# GD32VW553x register map
File version: 1.0
CPU: other RISC-V, little endian, no MPU, FPU
Registers are 32-bit, read-write, reset 0x0 unless marked. A register's access mark holds for its fields unless they carry their own. Offsets are from the block's base; [hi:lo] are bit positions; {n}, {i} and the like mark numbered series.

## RCU — Reset and clock unit
Base 0x40023800
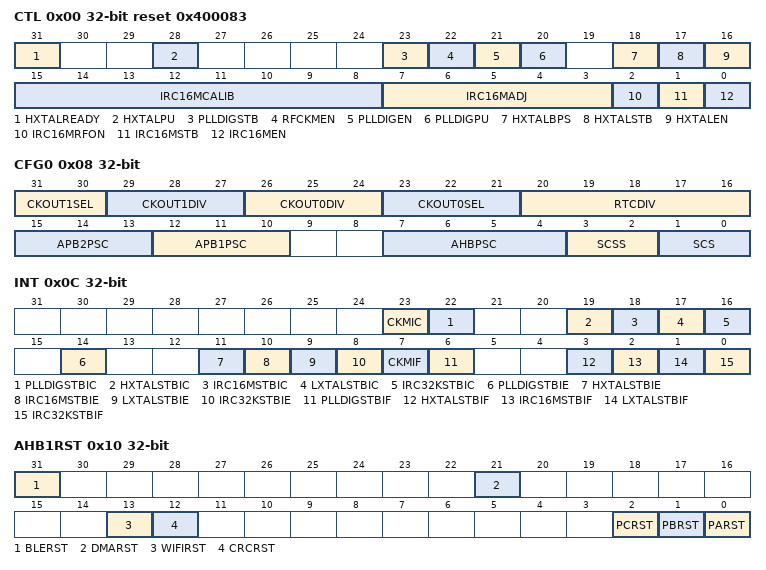
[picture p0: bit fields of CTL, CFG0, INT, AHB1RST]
0x00 CTL access per field reset 0x400083 — Control register
  [31] HXTALREADY rw — High speed crystal oscillator ready, set by software, which can be written when HXTALEN is off
  [28] HXTALPU rw — High speed crystal oscillator (HXTAL) power up, which can be written when HXTALEN is off
  [23] PLLDIGSTB ro — PLLDIG clock stabilization flag
  [22] RFCKMEN rw — HXTAL clock monitor enable, check RF XTAL
  [21] PLLDIGEN rw — PLLDIG enable, this bit cannot be reset if the PLLDIG clock is used as the system clock
  [20] PLLDIGPU rw — PLLDIG power up, this bit cannot be reset if the PLLDIG clock is used as the system clock
  [18] HXTALBPS rw — High speed crystal oscillator (HXTAL) clock bypass mode enable
  [17] HXTALSTB ro — High speed crystal oscillator (HXTAL) clock stabilization flag
  [16] HXTALEN rw — High speed crystal oscillator (HXTAL) enable
  [15:8] IRC16MCALIB ro — Internal 16 MHz RC Oscillator calibration value register
  [7:3] IRC16MADJ rw — Internal 16 MHz RC oscillator clock trim adjust value
  [2] IRC16MRFON rw — Internal 16 MHz RC RF differential clock signal enable
  [1] IRC16MSTB ro — IRC16M internal 16MHz RC oscillator stabilization flag
  [0] IRC16MEN rw — Internal 16 MHz RC oscillator enable
0x04 PLL — PLL(Phase Lock Loop) register
  [15] PLLDIGSEL — PLLDIG clock source selection
0x08 CFG0 access per field — Clock configuration register 0
  [31:30] CKOUT1SEL rw — CKOUT1 clock source selection
  [29:27] CKOUT1DIV rw — The CK_OUT1 divider which the CK_OUT1 frequency can be reduced
  [26:24] CKOUT0DIV rw — The CK_OUT0 divider which the CK_OUT0 frequency can be reduced
  [23:21] CKOUT0SEL rw — CKOUT0 clock source selection
  [20:16] RTCDIV rw — RTC clock divider factor
  [15:13] APB2PSC rw — APB2 prescaler selection
  [12:10] APB1PSC rw — APB1 prescaler selection
  [7:4] AHBPSC rw — AHB prescaler selection
  [3:2] SCSS ro — System clock switch status
  [1:0] SCS rw — System clock switch
0x0C INT access per field — Clock interrupt register
  [23] CKMIC wo — HXTAL clock stuck interrupt clear
  [22] PLLDIGSTBIC wo — PLLDIG stabilization interrupt clear
  [19] HXTALSTBIC wo — HXTAL stabilization interrupt clear
  [18] IRC16MSTBIC wo — IRC16M stabilization interrupt clear
  [17] LXTALSTBIC wo — LXTAL stabilization interrupt clear
  [16] IRC32KSTBIC wo — IRC32K Stabilization interrupt clear
  [14] PLLDIGSTBIE rw — PLLDIG stabilization interrupt enable
  [11] HXTALSTBIE rw — HXTAL stabilization interrupt enable
  [10] IRC16MSTBIE rw — IRC16M stabilization interrupt enable
  [9] LXTALSTBIE rw — LXTAL stabilization interrupt enable
  [8] IRC32KSTBIE rw — IRC32K stabilization interrupt enable
  [7] CKMIF ro — HXTAL clock stuck interrupt flag
  [6] PLLDIGSTBIF ro — PLLDIG stabilization interrupt flag
  [3] HXTALSTBIF ro — HXTAL stabilization interrupt flag
  [2] IRC16MSTBIF ro — IRC16M stabilization interrupt flag
  [1] LXTALSTBIF ro — LXTAL stabilization interrupt flag
  [0] IRC32KSTBIF ro — IRC32K stabilization interrupt flag
0x10 AHB1RST — AHB1 reset register
  [31] BLERST — BLE reset
  [21] DMARST — DMA reset
  [13] WIFIRST — WIFI reset
  [12] CRCRST — CRC reset
  [2] PCRST — GPIO port C reset
  [1] PBRST — GPIO port B reset
  [0] PARST — GPIO port A reset
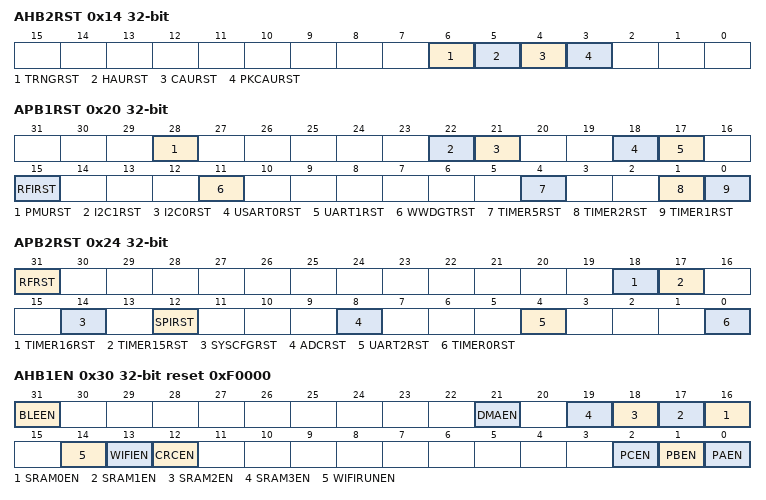
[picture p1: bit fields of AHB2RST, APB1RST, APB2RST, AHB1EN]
0x14 AHB2RST — AHB2 reset register
  [6] TRNGRST — TRNG reset
  [5] HAURST — HAU reset
  [4] CAURST — CAU reset
  [3] PKCAURST — PKCAU reset
0x18 AHB3RST — AHB3 reset register
  [1] QSPIRST — QSPI reset
0x20 APB1RST — APB1 reset register
  [28] PMURST — PMU reset
  [22] I2C1RST — I2C1 reset
  [21] I2C0RST — I2C0 reset
  [18] USART0RST — USART0 reset
  [17] UART1RST — UART1 reset
  [15] RFIRST — RFI reset
  [11] WWDGTRST — WWDGT reset
  [4] TIMER5RST — TIMER5 reset
  [1] TIMER2RST — TIMER2 reset
  [0] TIMER1RST — TIMER1 reset
0x24 APB2RST — APB2 reset register
  [31] RFRST — RF reset
  [18] TIMER16RST — TIMER16 reset
  [17] TIMER15RST — TIMER15 reset
  [14] SYSCFGRST — SYSCFG reset
  [12] SPIRST — SPI reset
  [8] ADCRST — ADC reset
  [4] UART2RST — UART2 reset
  [0] TIMER0RST — TIMER0 reset
0x30 AHB1EN reset 0xF0000 — AHB1 enable register
  [31] BLEEN — BLE clock enable
  [21] DMAEN — DMA clock enable
  [n+16] SRAM{n}EN (n=0..3) — SRAM{n} clock enable
  [14] WIFIRUNEN — WIFIRUNEN clock enable
  [13] WIFIEN — WIFI Module clock enable
  [12] CRCEN — CRC clock enable
  [2] PCEN — GPIO port C clock enable
  [1] PBEN — GPIO port B clock enable
  [0] PAEN — GPIO port A clock enable
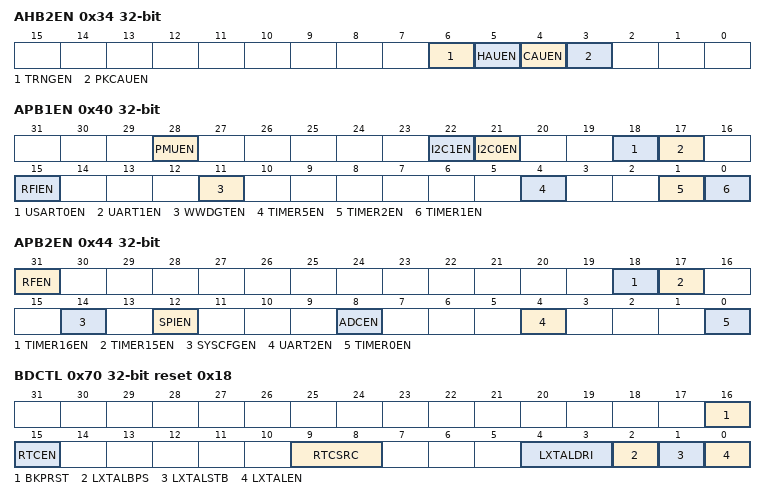
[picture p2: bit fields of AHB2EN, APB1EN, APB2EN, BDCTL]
0x34 AHB2EN — AHB2 enable register
  [6] TRNGEN — TRNG clock enable
  [5] HAUEN — HAU clock enable
  [4] CAUEN — CAU clock enable
  [3] PKCAUEN — PKCAU clock enable
0x38 AHB3EN — AHB3 enable register
  [1] QSPIEN — QSPI clock enable
0x40 APB1EN — APB1 enable register
  [28] PMUEN — PMU clock enable
  [22] I2C1EN — I2C1 clock enable
  [21] I2C0EN — I2C0 clock enable
  [18] USART0EN — USART0 clock enable
  [17] UART1EN — UART1 clock enable
  [15] RFIEN — RFI clock enable
  [11] WWDGTEN — WWDGT clock enable
  [4] TIMER5EN — TIMER5 clock enable
  [1] TIMER2EN — TIMER2 clock enable
  [0] TIMER1EN — TIMER1 clock enable
0x44 APB2EN — APB2 enable register
  [31] RFEN — RF clock enable
  [18] TIMER16EN — TIMER16 clock enable
  [17] TIMER15EN — TIMER15 clock enable
  [14] SYSCFGEN — SYSCFG clock enable
  [12] SPIEN — SPI clock enable
  [8] ADCEN — ADC clock enable
  [4] UART2EN — UART2 clock enable
  [0] TIMER0EN — TIMER0 clock enable
0x50 AHB1SPEN reset 0x8000 — AHB1 sleep mode enable register
  [15] FMCSPEN — FMC clock enable when sleep mode
0x70 BDCTL access per field reset 0x18 — Backup domain control register
  [16] BKPRST rw — Backup domain reset
  [15] RTCEN rw — RTC clock enable
  [9:8] RTCSRC rw — RTC clock entry selection
  [4:3] LXTALDRI rw — LXTAL drive capability
  [2] LXTALBPS rw — LXTAL bypass mode enable
  [1] LXTALSTB ro — Low speed crystal oscillator stabilization flag
  [0] LXTALEN rw — LXTAL enable
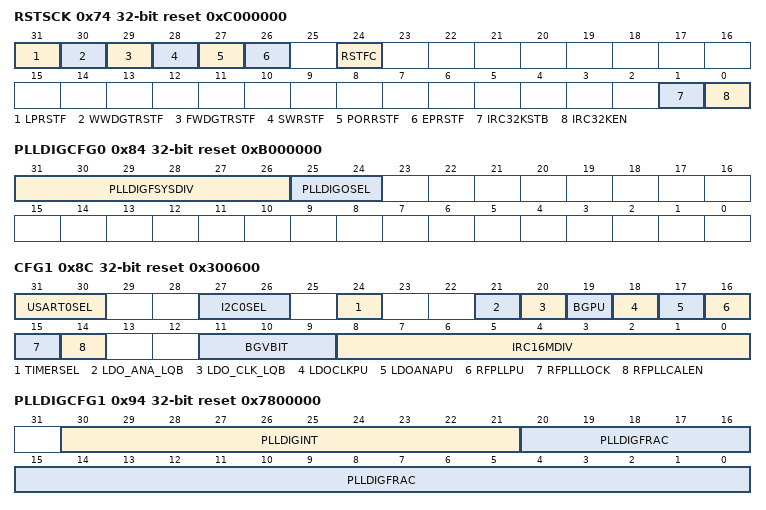
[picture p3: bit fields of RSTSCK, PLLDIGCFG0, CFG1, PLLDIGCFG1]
0x74 RSTSCK access per field reset 0xC000000 — Reset source / clock register
  [31] LPRSTF ro — Low-power reset flag
  [30] WWDGTRSTF ro — Window watchdog timer reset flag
  [29] FWDGTRSTF ro — Free watchdog timer reset flag
  [28] SWRSTF ro — Software reset flag
  [27] PORRSTF ro — Power reset flag
  [26] EPRSTF ro — External pin reset flag
  [24] RSTFC rw — Reset flag clear
  [1] IRC32KSTB ro — IRC32K stabilization flag
  [0] IRC32KEN rw — IRC32K enable
0x84 PLLDIGCFG0 reset 0xB000000 — PLLDIG clock configuration register 0
  [31:26] PLLDIGFSYSDIV — PLLDIG clock divider factor for system clock
  [25:24] PLLDIGOSEL — PLLDIG output frequency select
0x8C CFG1 access per field reset 0x300600 — Clock configuration register 1
  [31:30] USART0SEL rw — USART0 Clock Source Selection
  [27:26] I2C0SEL rw — I2C0 Clock Source Selection
  [24] TIMERSEL rw — TIMER clock selection
  [21] LDO_ANA_LQB rw — Analog LDO current bias mode selection
  [20] LDO_CLK_LQB rw — Clock LDO current bias mode selection
  [19] BGPU rw — BandGap power on enable
  [18] LDOCLKPU rw — LDO clock power on enable for RF / ADC / DAC
  [17] LDOANAPU rw — LDO analog power on enable for RF filter
  [16] RFPLLPU rw — RFPLL power on enable
  [15] RFPLLLOCK ro
  [14] RFPLLCALEN rw — RF PLL calculation enable
  [11:9] BGVBIT rw — BandGap Power adjust, which can not be written when HXTALEN or PLLDIGEN is on
  [8:0] IRC16MDIV rw — IRC16M clock divider factor for system clock
0x90 ADDCTL — Additional clock control register
  [5:1] RNGCKDIV — PLLDIG clock divider factor for TRNG clock
0x94 PLLDIGCFG1 reset 0x7800000 — PLLDIG clock configuration register 1
  [30:21] PLLDIGINT — Control PLLDIG frequency doubling factor for integer part
  [20:0] PLLDIGFRAC — Control PLLDIG frequency doubling factor for fractional part
0x100 VKEY wo — Voltage key register
  [31:0] KEY — The key of RCU_DSV register
0x134 DSV — Deep-sleep mode voltage register
  [1:0] DSLPVS — Deep-sleep mode voltage selection
